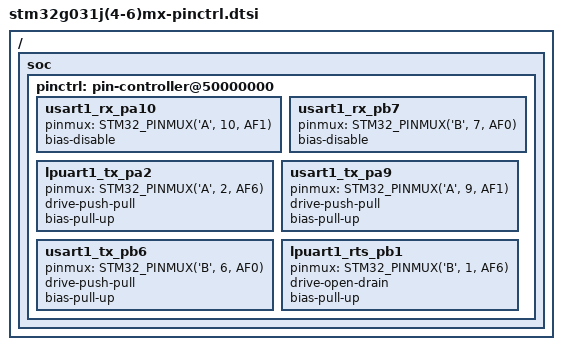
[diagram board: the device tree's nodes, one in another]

/*
 * NOTE: Autogenerated file using stm32_pinctrl_gen.py
 *
 * SPDX-License-Identifier: Apache-2.0
 */

#include <dt-bindings/pinctrl/stm32-pinctrl.h>

/ {
	soc {
		pinctrl: pin-controller@50000000 {
			/* UART_RX */
			usart1_rx_pa10: usart1_rx_pa10 {
				pinmux = <STM32_PINMUX('A', 10, AF1)>;
				bias-disable;
			};

			usart1_rx_pb7: usart1_rx_pb7 {
				pinmux = <STM32_PINMUX('B', 7, AF0)>;
				bias-disable;
			};


			/* UART_TX */
			lpuart1_tx_pa2: lpuart1_tx_pa2 {
				pinmux = <STM32_PINMUX('A', 2, AF6)>;
				drive-push-pull;
				bias-pull-up;
			};

			lpuart1_tx_pa2: lpuart1_tx_pa2 {
				pinmux = <STM32_PINMUX('A', 2, AF6)>;
				drive-push-pull;
				bias-pull-up;
			};

			usart1_tx_pa9: usart1_tx_pa9 {
				pinmux = <STM32_PINMUX('A', 9, AF1)>;
				drive-push-pull;
				bias-pull-up;
			};

			usart1_tx_pb6: usart1_tx_pb6 {
				pinmux = <STM32_PINMUX('B', 6, AF0)>;
				drive-push-pull;
				bias-pull-up;
			};


			/* UART_RTS */
			lpuart1_rts_pb1: lpuart1_rts_pb1 {
				pinmux = <STM32_PINMUX('B', 1, AF6)>;
				drive-open-drain;
				bias-pull-up;
			};

			lpuart1_rts_pb1: lpuart1_rts_pb1 {
				pinmux = <STM32_PINMUX('B', 1, AF6)>;
				drive-open-drain;
				bias-pull-up;
			};

		};
	};
};
